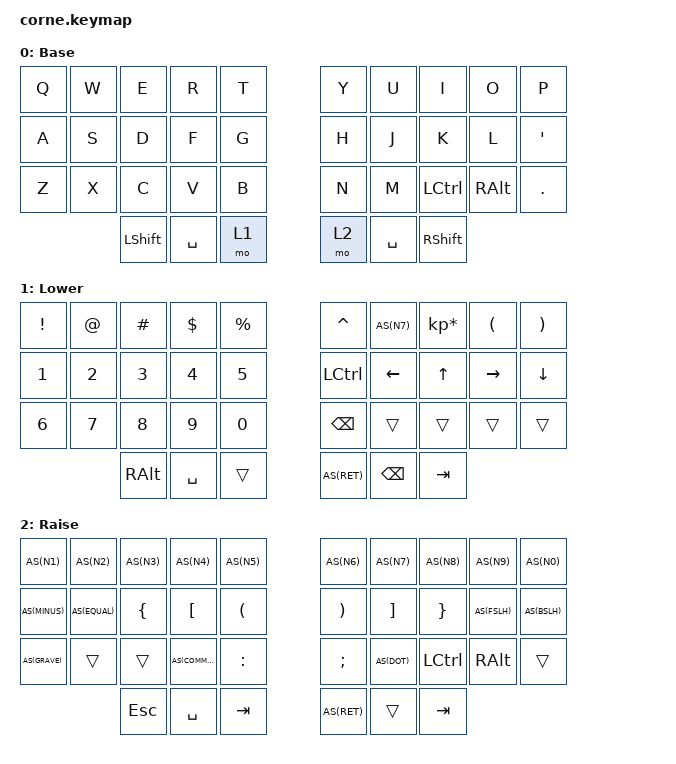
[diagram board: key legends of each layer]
/*
 * Copyright (c) 2020 The ZMK Contributors
 *
 * SPDX-License-Identifier: MIT
 */

#include <behaviors.dtsi>
#include <dt-bindings/zmk/keys.h>
#include <dt-bindings/zmk/bt.h>


#define AS(keycode) &as LS(keycode) keycode

/ {
    chosen {
      zmk,matrix_transform = &five_column_transform;
    };

    behaviors {
        as: auto_shift {
            compatible = "zmk,behavior-hold-tap";
            #binding-cells = <2>;
            tapping_term_ms = <350>;
            quick_tap_ms = <0>;
            flavor = "tap-preferred";
            bindings = <&kp>, <&kp>;
        };
    };
        keymap {
                compatible = "zmk,keymap";
                default_layer {
// DEFAULT
// ----------------------------------------------------------------------
// |  Q  |  W  |  E  |  R  |  T  |     |  Y  |  U   |  I   |  O   | P |
// |  A  |  S  |  D  |  F  |  G  |     |  H  |  J   |  K   |  L   | ' |
// |  Z  |  X  |  C  |  V  |  B  |     |  N  |  M   | CTRL | META | . |
// |           |Shift| SPC | LWR |     | RSE | SPC  | RS |            |
// ----------------------------------------------------------------------
//
                        display-name = "Base";
                        bindings = <
    &kp Q &kp W  &kp E  &kp R  &kp T     &kp Y    &kp U   &kp I      &kp O      &kp P 
   &kp A  &kp S  &kp D &kp F  &kp G      &kp H    &kp J   &kp K      &kp L      &kp SQT 
   &kp Z  &kp X  &kp C  &kp V  &kp B      &kp N    &kp M    &kp LCTL  &kp RALT  &kp DOT 
          &kp LSHIFT &kp SPACE &mo 1       &mo 2 &kp SPACE  &kp RSHIFT
                        >;
                };

                
                lower_layer {
// LOWER
// ----------------------------------------------------------------------
// | !  |  @  |  #  |  $  |  %  |     |  ^  |  &  |  *  |  (  |  )    |
// | 1  |  2  |  3  |  4  |  5  |     | CLFT| Lft | UP  | Rgt | DWN   |
// | 6  |  7  |  8  |  9  |  0  |     | BSPC|     |     |     |       |
// |          | RALT| SPC |     |     | ENT | bksp| TAB |             |
// ----------------------------------------------------------------------
//

                        display-name = "Lower";
                        bindings = <
   &kp EXCL  &kp AT   &kp HASH  &kp DLLR  &kp PRCNT    &kp CARET AS(N7) &kp KP_MULTIPLY &kp LPAR  &kp RPAR
   &kp N1    &kp N2   &kp N3    &kp N4    &kp N5       &kp LCTL  &kp LEFT &kp UP    &kp RIGHT &kp DOWN      
   &kp N6    &kp N7   &kp N8    &kp N9    &kp N0       &kp BSPC  &trans    &trans  &trans    &trans 
                      &kp RALT &kp SPACE &trans   AS(RET)   &kp BSPC  &kp TAB 
                       >;
                };

                raise_layer {
// RAISE
// ----------------------------------------------------------------------
// | 1! |  2@ |  3# |  4$ |  5% |     |  6^ |  7& |  8* |  9(  |  0)  |
// | -_ |  =+ |  {  |  [  |  (  |     |  )  |  ]  |  }  |  /?  |  \|  |
// | `~ |     |     |  ,< |  :  |     |  ;  |  .> | CTRL| META |      |
// |          | ESC | SPC | TAB |     | ENT |     | TAB |             |
// ----------------------------------------------------------------------
//
                        display-name = "Raise";
                        bindings = <

   AS(N1)    AS(N2)    AS(N3)    AS(N4)    AS(N5)        AS(N6)    AS(N7)    AS(N8)    AS(N9)   AS(N0)
   AS(MINUS) AS(EQUAL) &kp LBRC  &kp LBKT  &kp LPAR      &kp RPAR  &kp RBKT  &kp RBRC  AS(FSLH) AS(BSLH)
   AS(GRAVE) &trans    &trans    AS(COMMA) &kp COLON     &kp SEMI  AS(DOT)   &kp LCTRL &kp RALT &trans
                       &kp ESC  &kp SPACE   &kp TAB     AS(RET)   &trans    &kp TAB
                        >;
                };
        };
};
